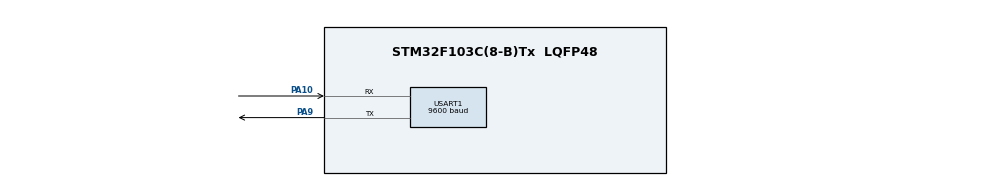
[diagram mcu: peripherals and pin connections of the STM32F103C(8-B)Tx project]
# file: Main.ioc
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Mcu.Family=STM32F1
Mcu.Name=STM32F103C(8-B)Tx
Mcu.Package=LQFP48
NVIC.PriorityGroup=NVIC_PRIORITYGROUP_4
PA10.Mode=Asynchronous
PA10.Signal=USART1_RX
PA13.Mode=JTAG_4_pins
PA13.Signal=SYS_JTMS-SWDIO
PA14.Mode=JTAG_4_pins
PA14.Signal=SYS_JTCK-SWCLK
PA15.Mode=JTAG_4_pins
PA15.Signal=SYS_JTDI
PA9.Mode=Asynchronous
PA9.Signal=USART1_TX
PB3.Mode=JTAG_4_pins
PB3.Signal=SYS_JTDO-TRACESWO
ProjectManager.HeapSize=0x200
ProjectManager.StackSize=0x400
ProjectManager.TargetToolchain=MDK-ARM V5.27
RCC.APB1Freq_Value=8000000
RCC.APB2Freq_Value=8000000
USART1.BaudRate=9600
USART1.Mode=MODE_TX
USART1.VirtualMode=VM_ASYNC
VP_CRC_VS_CRC.Mode=CRC_Activate
board=custom

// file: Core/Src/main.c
/* USER CODE BEGIN Header */
/**
  ******************************************************************************
  * @file           : main.c
  * @brief          : Main program body
  ******************************************************************************
  * @attention
  *
  * <h2><center>&copy; Copyright (c) 2021 STMicroelectronics.
  * All rights reserved.</center></h2>
  *
  * This software component is licensed by ST under BSD 3-Clause license,
  * the "License"; You may not use this file except in compliance with the
  * License. You may obtain a copy of the License at:
  *                        opensource.org/licenses/BSD-3-Clause
  *
  ******************************************************************************
  */
/* USER CODE END Header */
#include "main.h"

/* USER CODE BEGIN Includes */
#include <stdio.h>
#include "aj_crc32.h"
/* USER CODE END Includes */

void SystemClock_Config(void);
static void MX_GPIO_Init(void);
static void MX_USART1_UART_Init(void);
static void MX_CRC_Init(void);

/* USER CODE BEGIN PFP */
static void LL_USART_TransmitString(USART_TypeDef *USARTx, const char *str);
/* USER CODE END PFP */

int main(void){

  /* USER CODE BEGIN 1 */
	uint32_t data[3]={0x10,0x43,0x63};
	char txt[20];
	uint32_t crc32 = 0;
  /* USER CODE END 1 */

  /* MCU Configuration--------------------------------------------------------*/

  /* Reset of all peripherals, Initializes the Flash interface and the Systick. */
  LL_APB2_GRP1_EnableClock(LL_APB2_GRP1_PERIPH_AFIO);
  LL_APB1_GRP1_EnableClock(LL_APB1_GRP1_PERIPH_PWR);

  /* System interrupt init*/
  NVIC_SetPriorityGrouping(NVIC_PRIORITYGROUP_4);

  /** NONJTRST: Full SWJ (JTAG-DP + SW-DP) but without NJTRST
  */
  LL_GPIO_AF_Remap_SWJ_NONJTRST();

  /* Configure the system clock */
  SystemClock_Config();

  /* Initialize all configured peripherals */
  MX_GPIO_Init();
  MX_USART1_UART_Init();
  MX_CRC_Init();

  /* Infinite loop */
  /* USER CODE BEGIN WHILE */
	LL_USART_TransmitString(USART1, "Reset CRC-32: \r");
	AJ_CRC32_ResetUnit();
	crc32 = AJ_CRC32_ReadData();
	sprintf(txt, "CRC32 = 0x%2X\r \r", crc32);
	LL_USART_TransmitString(USART1, txt);

	LL_USART_TransmitString(USART1, "Feed CRC-32: \r");
	for(uint32_t i=0; i<3; i++){
		AJ_CRC32_FeedData(data[i]);
		sprintf(txt, "Data[%1d] = 0x%2X\r", i, data[i]);
		LL_USART_TransmitString(USART1, txt);
	}
	crc32 = AJ_CRC32_ReadData();
	sprintf(txt, "CRC32 = 0x%2X\r", crc32);
	LL_USART_TransmitString(USART1, txt);

  while(1){
    /* USER CODE END WHILE */
  }
}

void SystemClock_Config(void)
{
  LL_FLASH_SetLatency(LL_FLASH_LATENCY_0);
  while(LL_FLASH_GetLatency()!= LL_FLASH_LATENCY_0)
  {
  }
  LL_RCC_HSI_SetCalibTrimming(16);
  LL_RCC_HSI_Enable();

   /* Wait till HSI is ready */
  while(LL_RCC_HSI_IsReady() != 1)
  {

  }
  LL_RCC_SetAHBPrescaler(LL_RCC_SYSCLK_DIV_1);
  LL_RCC_SetAPB1Prescaler(LL_RCC_APB1_DIV_1);
  LL_RCC_SetAPB2Prescaler(LL_RCC_APB2_DIV_1);
  LL_RCC_SetSysClkSource(LL_RCC_SYS_CLKSOURCE_HSI);

   /* Wait till System clock is ready */
  while(LL_RCC_GetSysClkSource() != LL_RCC_SYS_CLKSOURCE_STATUS_HSI)
  {

  }
  LL_Init1msTick(8000000);
  LL_SetSystemCoreClock(8000000);
}

static void MX_CRC_Init(void)
{

  /* Peripheral clock enable */
  LL_AHB1_GRP1_EnableClock(LL_AHB1_GRP1_PERIPH_CRC);

}

static void MX_USART1_UART_Init(void)
{

  LL_USART_InitTypeDef USART_InitStruct = {0};

  LL_GPIO_InitTypeDef GPIO_InitStruct = {0};

  /* Peripheral clock enable */
  LL_APB2_GRP1_EnableClock(LL_APB2_GRP1_PERIPH_USART1);

  LL_APB2_GRP1_EnableClock(LL_APB2_GRP1_PERIPH_GPIOA);
  /**USART1 GPIO Configuration
  PA9   ------> USART1_TX
  PA10   ------> USART1_RX
  */
  GPIO_InitStruct.Pin = LL_GPIO_PIN_9;
  GPIO_InitStruct.Mode = LL_GPIO_MODE_ALTERNATE;
  GPIO_InitStruct.Speed = LL_GPIO_SPEED_FREQ_HIGH;
  GPIO_InitStruct.OutputType = LL_GPIO_OUTPUT_PUSHPULL;
  LL_GPIO_Init(GPIOA, &GPIO_InitStruct);

  GPIO_InitStruct.Pin = LL_GPIO_PIN_10;
  GPIO_InitStruct.Mode = LL_GPIO_MODE_FLOATING;
  LL_GPIO_Init(GPIOA, &GPIO_InitStruct);

  USART_InitStruct.BaudRate = 9600;
  USART_InitStruct.DataWidth = LL_USART_DATAWIDTH_8B;
  USART_InitStruct.StopBits = LL_USART_STOPBITS_1;
  USART_InitStruct.Parity = LL_USART_PARITY_NONE;
  USART_InitStruct.TransferDirection = LL_USART_DIRECTION_TX;
  USART_InitStruct.HardwareFlowControl = LL_USART_HWCONTROL_NONE;
  USART_InitStruct.OverSampling = LL_USART_OVERSAMPLING_16;
  LL_USART_Init(USART1, &USART_InitStruct);
  LL_USART_ConfigAsyncMode(USART1);
  LL_USART_Enable(USART1);

}

static void MX_GPIO_Init(void)
{

  /* GPIO Ports Clock Enable */
  LL_APB2_GRP1_EnableClock(LL_APB2_GRP1_PERIPH_GPIOA);
  LL_APB2_GRP1_EnableClock(LL_APB2_GRP1_PERIPH_GPIOB);

}

/* USER CODE BEGIN 4 */
void LL_USART_TransmitString(USART_TypeDef *USARTx, const char *str){
  while(*str != 0){
		while(LL_USART_IsActiveFlag_TXE(USARTx) != 1){}		// Transmit Data Register Empty
		LL_USART_TransmitData8(USARTx, *str);
    str++;
	}
}
/* USER CODE END 4 */

void Error_Handler(void)
{
}
